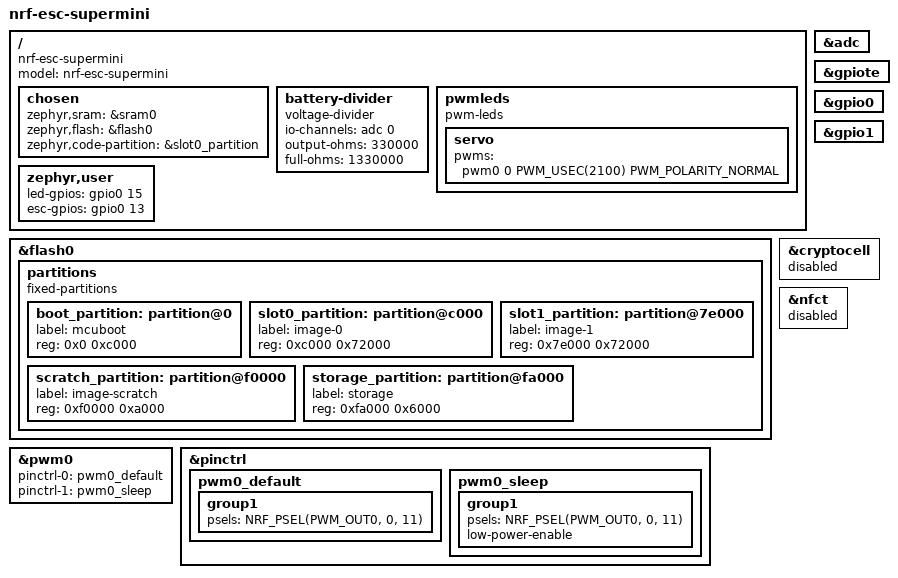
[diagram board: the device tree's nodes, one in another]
// Copyright (c) 2024 Nordic Semiconductor ASA
// SPDX-License-Identifier: Apache-2.0

/dts-v1/;
#include <nordic/nrf52840_qiaa.dtsi>

/ {
	model = "nrf-esc-supermini";
	compatible = "nrf-esc-supermini";

	chosen {
		zephyr,sram = &sram0;
		zephyr,flash = &flash0;
		zephyr,code-partition = &slot0_partition;
	};

	battery-divider {
		compatible = "voltage-divider";
		status = "okay";
		io-channels = <&adc 0>; // Measure VDDHDIV5
		output-ohms = <330000>;
		full-ohms = <1330000>;
	};

	pwmleds {
		compatible = "pwm-leds";
		servo: servo {
			pwms = <&pwm0 0 PWM_USEC(2100) PWM_POLARITY_NORMAL>;
		};
	};

	zephyr,user {
		led-gpios = <&gpio0 15 GPIO_OPEN_SOURCE>;
		esc-gpios = <&gpio0 13 0>;
	};

};

&flash0 {
	partitions {
		compatible = "fixed-partitions";
		#address-cells = <1>;
		#size-cells = <1>;

		boot_partition: partition@0 {
			label = "mcuboot";
			reg = <0x0 0xc000>;
		};
		slot0_partition: partition@c000 {
			label = "image-0";
			reg = <0xc000 0x72000>;
		};
		slot1_partition: partition@7e000 {
			label = "image-1";
			reg = <0x7e000 0x72000>;
		};
		scratch_partition: partition@f0000 {
			label = "image-scratch";
			reg = <0xf0000 0xa000>;
		};
		storage_partition: partition@fa000 {
			label = "storage";
			reg = <0xfa000 0x6000>;
		};
	};
};

&adc {
	status = "okay";
};

&gpiote {
	status = "okay";
};

&gpio0 {
	status = "okay";
};

&gpio1 {
	status = "okay";
};

&pwm0 {
	status = "okay";
	pinctrl-0 = <&pwm0_default>;
	pinctrl-1 = <&pwm0_sleep>;
	pinctrl-names = "default", "sleep";
};

&pinctrl {
	pwm0_default: pwm0_default {
		group1 {
			psels = <NRF_PSEL(PWM_OUT0, 0, 11)>;
		};
	};
	pwm0_sleep: pwm0_sleep {
		group1 {
			psels = <NRF_PSEL(PWM_OUT0, 0, 11)>;
            low-power-enable;
		};
	};
};

&cryptocell {
	status = "disabled";
};

&nfct {
	status = "disabled";
};
